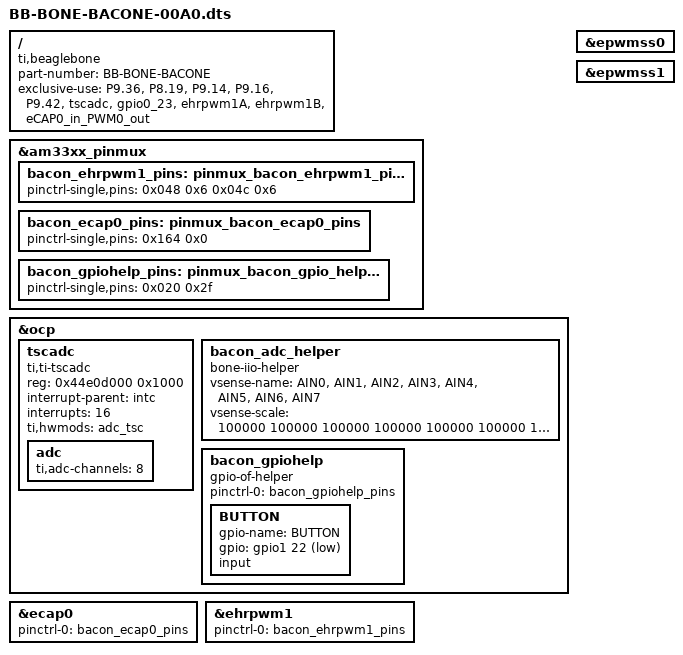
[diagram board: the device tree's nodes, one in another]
/*
 * Copyright (C) 2013 Circuit Co.
 *
 * This program is free software; you can redistribute it and/or modify
 * it under the terms of the GNU General Public License version 2 as
 * published by the Free Software Foundation.
 */
/dts-v1/;
/plugin/;

/ {
	compatible = "ti,beaglebone", "ti,beaglebone-black";

	/* identification */
	part-number = "BB-BONE-BACONE";

	/* state the resources this cape uses */
	exclusive-use =
		/* the pin header uses */
		"P9.36",	/* AIN5 */
		"P8.19",	/* gpio-keys: gpio0_23 */
		"P9.14",	/* pwm: ehrpwm1A */
		"P9.16",	/* pwm: ehrpwm1B */
		"P9.42",	/* pwm: eCAP0_in_PWM0_out */
		/* the hardware IP uses */
		"tscadc",
		"gpio0_23",
		"ehrpwm1A",
		"ehrpwm1B",
		"eCAP0_in_PWM0_out";
	fragment@0 {
		target = <&am33xx_pinmux>;
		__overlay__ {

			bacon_ehrpwm1_pins: pinmux_bacon_ehrpwm1_pins {
				pinctrl-single,pins = <
					0x048  0x6	/* P9_14 (ZCZ ball U14) | MODE 6 */
					0x04c  0x6	/* P9_16 (ZCZ ball T14) | MODE 6 */
				>;
			};

			bacon_ecap0_pins: pinmux_bacon_ecap0_pins {
				pinctrl-single,pins = <
					0x164  0x0	/* P9_42 (ZCZ ball C18) | MODE 0 */
				>;
			};

			bacon_gpiohelp_pins: pinmux_bacon_gpio_helper_pins {
				pinctrl-single,pins = <
					0x020 0x2f	/* gpmc_ad8.gpio0_22, INPUT | PULLDIS | MODE7 */
				>;
			};
		};
	};

	fragment@1 {
		target = <&ocp>;
		__overlay__ {
			/* avoid stupid warning */
			#address-cells = <1>;
			#size-cells = <1>;

			tscadc {
				compatible = "ti,ti-tscadc";
				reg = <0x44e0d000 0x1000>;

				interrupt-parent = <&intc>;
				interrupts = <16>;
				ti,hwmods = "adc_tsc";
				status = "okay";

				adc {
					ti,adc-channels = <8>;	/* 8 channels (but only 5 is used) */
				};
			};

			bacon_adc_helper {
				compatible = "bone-iio-helper";
				vsense-name  = "AIN0", "AIN1", "AIN2", "AIN3", "AIN4", "AIN5", "AIN6", "AIN7";
				/* report micro-volts */
				vsense-scale = <100000  100000  100000  100000  100000  100000  100000  100000>;
				status = "okay";
			};
		};
	};

	fragment@3 {
		target = <&epwmss0>;
		__overlay__ {
			status = "okay";
		};
	};

	fragment@4 {
		target = <&ecap0>;
		__overlay__ {
			pinctrl-names = "default";
			pinctrl-0 = <&bacon_ecap0_pins>;
			status = "okay";
		};
	};

	fragment@5 {
		target = <&epwmss1>;
		__overlay__ {
			status = "okay";
		};
	};

	fragment@6 {
		target = <&ehrpwm1>;
		__overlay__ {
			pinctrl-names = "default";
			pinctrl-0 = <&bacon_ehrpwm1_pins>;
			status = "okay";
		};
	};

	fragment@8 {
		target = <&ocp>;
		__overlay__ {

			bacon_gpiohelp {
				compatible = "gpio-of-helper";
				status = "okay";
				pinctrl-names = "default";
				pinctrl-0 = <&bacon_gpiohelp_pins>;

				/* declare your gpios */
				BUTTON {
					gpio-name = "BUTTON";
					gpio = <&gpio1 22 0x01>;	/* gpio1 is gpio0 */
					input;
				};
			};
		};
	};
};
